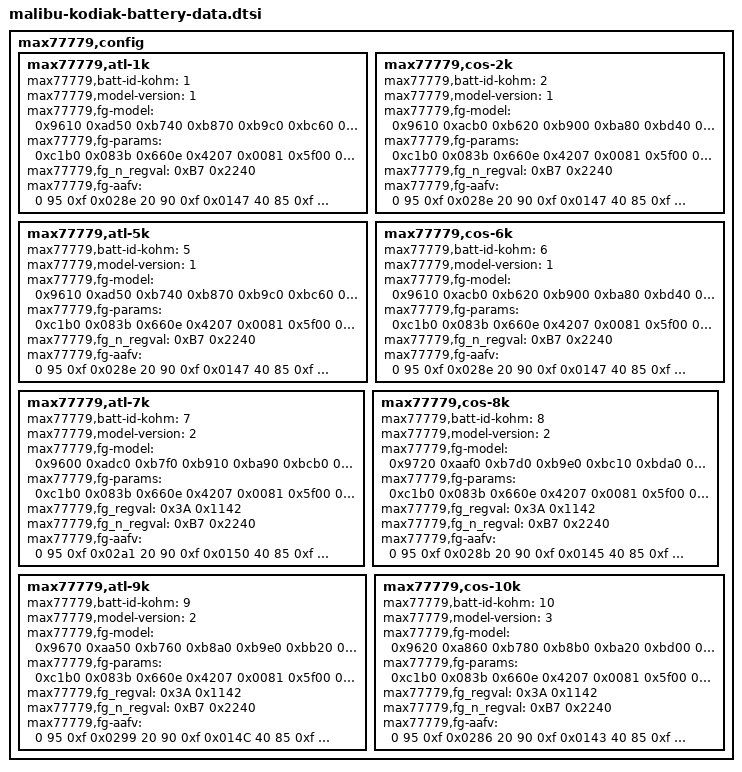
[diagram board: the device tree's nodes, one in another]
// SPDX-License-Identifier: GPL-2.0-only
/*
 * Battery device tree entries
 *
 * Copyright 2025 Google LLC
 *
 */
max77779,config {
	/* PKK4_ATL_3752_001_Proxy_Stacked_G1.ini.txt, b/418260018#comment2 */
	max77779,atl-1k {
		max77779,batt-id-kohm = <1>;
		max77779,model-version = <1>;
		max77779,fg-model = /bits/ 16 <
			0x9610 0xad50 0xb740 0xb870 0xb9c0 0xbc60 0xbe00 0xc100
			0xc2b0 0xc690 0xcaa0 0xcef0 0xd2a0 0xd840 0xdb20 0xdea0
			0x0040 0x01c0 0x1180 0x0c50 0x0d00 0x1260 0x1190 0x0ef0
			0x06d0 0x0700 0x0710 0x06d0 0x06c0 0x07e0 0x06e0 0x06e0
		>;
		max77779,fg-params = /bits/ 16 <
			/* 0x00C0 */	0xc1b0	/* nnvcfg0 */
			/* 0x00B6 */	0x083b	/* nrelaxcfg */
			/* 0x009F */	0x660e	/* nLearnCFG */
			/* 0x000C */	0x4207	/* Config */
			/* 0x00AB */	0x0081	/* Config2 */
			/* 0x00BC */	0x5f00	/* nFullSOCThr */
			/* 0x00A9 */	0x07fc	/* nfullcaprep */
			/* 0x00B3 */	0x07fc	/* ndesigncap */
			/* 0x0046 */	0x0c80	/* dPacc */
			/* 0x00A5 */	0x07fc	/* nfullcapnom */
			/* 0x00C6 */	0xa55a	/* nVEmpty */
			/* 0x00A0 */	0x2e0a	/* nQRTable00 */
			/* 0x00A1 */	0x1582	/* nQRTable10 */
			/* 0x00A2 */	0x0a00	/* nQRTable20 */
			/* 0x00A3 */	0x0780	/* nQRTable30 */
			/* 0x00A6 */	0x0400	/* nRCOMP0 */
			/* 0x00A7 */	0x1402	/* nTempCo */
			/* 0x009C */	0x028e	/* nichgterm */
			/* 0x00B2 */	0x3870	/* nmisccfg */
			/* 0x009E */	0x0400	/* nModelCfg */
			/* 0x00CA */	0xc8ff	/* nThermCfg */
			/* 0x009D */	0xcea4	/* nFilterCfg */
		>;
		max77779,fg_n_regval = /bits/ 16 <
			0xB7 0x2240	/* nConvgCfg */
		>;
		max77779,fg-aafv = /bits/ 32 <
			  0   95  0xf  0x028e
			 20   90  0xf  0x0147
			 40   85  0xf  0x0147
			 60   80  0xf  0x0147
			 80   75  0xf  0x0147
			100   70  0xf  0x0147
		>;
	};

	/* PKK4_COS_3753_001_Proxy_G1.ini.txt, b/418261687#comment3 */
	max77779,cos-2k {
		max77779,batt-id-kohm = <2>;
		max77779,model-version = <1>;
		max77779,fg-model = /bits/ 16 <
			0x9610 0xacb0 0xb620 0xb900 0xba80 0xbd40 0xc030 0xc300
			0xc680 0xca50 0xce10 0xcf00 0xd200 0xd5c0 0xd8c0 0xdfb0
			0x0040 0x0210 0x08b0 0x0c20 0x0ef0 0x0eb0 0x0ff0 0x07e0
			0x06b0 0x06f0 0x0890 0x06b0 0x05f0 0x07e0 0x06f0 0x06f0
		>;
		max77779,fg-params = /bits/ 16 <
			/* 0x00C0 */	0xc1b0	/* nnvcfg0 */
			/* 0x00B6 */	0x083b	/* nrelaxcfg */
			/* 0x009F */	0x660e	/* nLearnCFG */
			/* 0x000C */	0x4207	/* Config */
			/* 0x00AB */	0x0081	/* Config2 */
			/* 0x00BC */	0x5f00	/* nFullSOCThr */
			/* 0x00A9 */	0x07fc	/* nfullcaprep */
			/* 0x00B3 */	0x07fc	/* ndesigncap */
			/* 0x0046 */	0x0c80	/* dPacc */
			/* 0x00A5 */	0x07fc	/* nfullcapnom */
			/* 0x00C6 */	0xa55a	/* nVEmpty */
			/* 0x00A0 */	0x1e0c	/* nQRTable00 */
			/* 0x00A1 */	0x0f06	/* nQRTable10 */
			/* 0x00A2 */	0x0784	/* nQRTable20 */
			/* 0x00A3 */	0x0504	/* nQRTable30 */
			/* 0x00A6 */	0x0380	/* nRCOMP0 */
			/* 0x00A7 */	0x1402	/* nTempCo */
			/* 0x009C */	0x028e	/* nichgterm */
			/* 0x00B2 */	0x3870	/* nmisccfg */
			/* 0x009E */	0x0400	/* nModelCfg */
			/* 0x00CA */	0xc8ff	/* nThermCfg */
			/* 0x009D */	0xcea4	/* nFilterCfg */
		>;
		max77779,fg_n_regval = /bits/ 16 <
			0xB7 0x2240	/* nConvgCfg */
		>;
		max77779,fg-aafv = /bits/ 32 <
			  0   95  0xf  0x028e
			 20   90  0xf  0x0147
			 40   85  0xf  0x0147
			 60   80  0xf  0x0147
			 80   75  0xf  0x0147
			100   70  0xf  0x0147
		>;
	};

	/* PKK4_ATL_3752_001_Proxy_Stacked_G1.ini.txt, b/418260018#comment2 */
	max77779,atl-5k {
		max77779,batt-id-kohm = <5>; /* ATL-W */
		max77779,model-version = <1>;
		max77779,fg-model = /bits/ 16 <
			0x9610 0xad50 0xb740 0xb870 0xb9c0 0xbc60 0xbe00 0xc100
			0xc2b0 0xc690 0xcaa0 0xcef0 0xd2a0 0xd840 0xdb20 0xdea0
			0x0040 0x01c0 0x1180 0x0c50 0x0d00 0x1260 0x1190 0x0ef0
			0x06d0 0x0700 0x0710 0x06d0 0x06c0 0x07e0 0x06e0 0x06e0
		>;
		max77779,fg-params = /bits/ 16 <
			/* 0x00C0 */	0xc1b0	/* nnvcfg0 */
			/* 0x00B6 */	0x083b	/* nrelaxcfg */
			/* 0x009F */	0x660e	/* nLearnCFG */
			/* 0x000C */	0x4207	/* Config */
			/* 0x00AB */	0x0081	/* Config2 */
			/* 0x00BC */	0x5f00	/* nFullSOCThr */
			/* 0x00A9 */	0x07fc	/* nfullcaprep */
			/* 0x00B3 */	0x07fc	/* ndesigncap */
			/* 0x0046 */	0x0c80	/* dPacc */
			/* 0x00A5 */	0x07fc	/* nfullcapnom */
			/* 0x00C6 */	0xa55a	/* nVEmpty */
			/* 0x00A0 */	0x2e0a	/* nQRTable00 */
			/* 0x00A1 */	0x1582	/* nQRTable10 */
			/* 0x00A2 */	0x0a00	/* nQRTable20 */
			/* 0x00A3 */	0x0780	/* nQRTable30 */
			/* 0x00A6 */	0x0400	/* nRCOMP0 */
			/* 0x00A7 */	0x1402	/* nTempCo */
			/* 0x009C */	0x028e	/* nichgterm */
			/* 0x00B2 */	0x3870	/* nmisccfg */
			/* 0x009E */	0x0400	/* nModelCfg */
			/* 0x00CA */	0xc8ff	/* nThermCfg */
			/* 0x009D */	0xcea4	/* nFilterCfg */
		>;
		max77779,fg_n_regval = /bits/ 16 <
			0xB7 0x2240	/* nConvgCfg */
		>;
		max77779,fg-aafv = /bits/ 32 <
			  0   95  0xf  0x028e
			 20   90  0xf  0x0147
			 40   85  0xf  0x0147
			 60   80  0xf  0x0147
			 80   75  0xf  0x0147
			100   70  0xf  0x0147
		>;
	};

	/* PKK4_COS_3753_001_Proxy_G1.ini.txt, b/418261687#comment3 */
	max77779,cos-6k {
		max77779,batt-id-kohm = <6>; /* COS-W */
		max77779,model-version = <1>;
		max77779,fg-model = /bits/ 16 <
			0x9610 0xacb0 0xb620 0xb900 0xba80 0xbd40 0xc030 0xc300
			0xc680 0xca50 0xce10 0xcf00 0xd200 0xd5c0 0xd8c0 0xdfb0
			0x0040 0x0210 0x08b0 0x0c20 0x0ef0 0x0eb0 0x0ff0 0x07e0
			0x06b0 0x06f0 0x0890 0x06b0 0x05f0 0x07e0 0x06f0 0x06f0
		>;
		max77779,fg-params = /bits/ 16 <
			/* 0x00C0 */	0xc1b0	/* nnvcfg0 */
			/* 0x00B6 */	0x083b	/* nrelaxcfg */
			/* 0x009F */	0x660e	/* nLearnCFG */
			/* 0x000C */	0x4207	/* Config */
			/* 0x00AB */	0x0081	/* Config2 */
			/* 0x00BC */	0x5f00	/* nFullSOCThr */
			/* 0x00A9 */	0x07fc	/* nfullcaprep */
			/* 0x00B3 */	0x07fc	/* ndesigncap */
			/* 0x0046 */	0x0c80	/* dPacc */
			/* 0x00A5 */	0x07fc	/* nfullcapnom */
			/* 0x00C6 */	0xa55a	/* nVEmpty */
			/* 0x00A0 */	0x1e0c	/* nQRTable00 */
			/* 0x00A1 */	0x0f06	/* nQRTable10 */
			/* 0x00A2 */	0x0784	/* nQRTable20 */
			/* 0x00A3 */	0x0504	/* nQRTable30 */
			/* 0x00A6 */	0x0380	/* nRCOMP0 */
			/* 0x00A7 */	0x1402	/* nTempCo */
			/* 0x009C */	0x028e	/* nichgterm */
			/* 0x00B2 */	0x3870	/* nmisccfg */
			/* 0x009E */	0x0400	/* nModelCfg */
			/* 0x00CA */	0xc8ff	/* nThermCfg */
			/* 0x009D */	0xcea4	/* nFilterCfg */
		>;
		max77779,fg_n_regval = /bits/ 16 <
			0xB7 0x2240	/* nConvgCfg */
		>;
		max77779,fg-aafv = /bits/ 32 <
			  0   95  0xf  0x028e
			 20   90  0xf  0x0147
			 40   85  0xf  0x0147
			 60   80  0xf  0x0147
			 80   75  0xf  0x0147
			100   70  0xf  0x0147
		>;
	};

	/* PKK4_ATL_4059_StackingD.ini.txt, b/467524492#comment2 */
	max77779,atl-7k {
		max77779,batt-id-kohm = <7>; /* ATL-S-SY-6/9 */
		max77779,model-version = <2>;
		max77779,fg-model = /bits/ 16 <
			0x9600 0xadc0 0xb7f0 0xb910 0xba90 0xbcb0 0xbe40 0xc100
			0xc2e0 0xc620 0xc9c0 0xcd50 0xd090 0xd580 0xdb20 0xe070
			0x0020 0x0180 0x1550 0x0ed0 0x0e40 0x1730 0x10d0 0x0bf0
			0x07e0 0x0730 0x06b0 0x06d0 0x05d0 0x07a0 0x05a0 0x05a0
		>;
		max77779,fg-params = /bits/ 16 <
			/* 0x00C0 */	0xc1b0	/* nnvcfg0 */
			/* 0x00B6 */	0x083b	/* nrelaxcfg */
			/* 0x009F */	0x660e	/* nLearnCFG */
			/* 0x000C */	0x4207	/* Config */
			/* 0x00AB */	0x0081	/* Config2 */
			/* 0x00BC */	0x5f00	/* nFullSOCThr */
			/* 0x00A9 */	0x083a	/* nfullcaprep */
			/* 0x00B3 */	0x083a	/* ndesigncap */
			/* 0x0046 */	0x0c80	/* dPacc */
			/* 0x00A5 */	0x083a	/* nfullcapnom */
			/* 0x00C6 */	0xa55a	/* nVEmpty */
			/* 0x00A0 */	0x280c	/* nQRTable00 */
			/* 0x00A1 */	0x1408	/* nQRTable10 */
			/* 0x00A2 */	0x0a00	/* nQRTable20 */
			/* 0x00A3 */	0x0680	/* nQRTable30 */
			/* 0x00A6 */	0x0440	/* nRCOMP0 */
			/* 0x00A7 */	0x1803	/* nTempCo */
			/* 0x009C */	0x02a1	/* nichgterm */
			/* 0x00B2 */	0x3870	/* nmisccfg */
			/* 0x009E */	0x0400	/* nModelCfg */
			/* 0x00CA */	0xc8ff	/* nThermCfg */
			/* 0x009D */	0xcea4	/* nFilterCfg */
		>;
		max77779,fg_regval = /bits/ 16 <
			0x3A 0x1142	/* SOCHold */
		>;
		max77779,fg_n_regval = /bits/ 16 <
			0xB7 0x2240	/* nConvgCfg */
		>;
		max77779,fg-aafv = /bits/ 32 <
			  0   95  0xf  0x02a1
			 20   90  0xf  0x0150
			 40   85  0xf  0x0150
			 60   80  0xf  0x0150
			 80   75  0xf  0x0150
			100   70  0xf  0x0150
		>;
	};

	/* PKK4_COS_4050_StackingB.ini.txt, b/471328077#comment2 */
	max77779,cos-8k {
		max77779,batt-id-kohm = <8>; /* COS-S_SY-8/10 */
		max77779,model-version = <2>;
		max77779,fg-model = /bits/ 16 <
			0x9720 0xaaf0 0xb7d0 0xb9e0 0xbc10 0xbda0 0xbfe0 0xc270
			0xc650 0xca70 0xce40 0xd1e0 0xd5a0 0xd8f0 0xdce0 0xe040
			0x0040 0x0180 0x1000 0x0ef0 0x1120 0x1250 0x0df0 0x07f0
			0x06c0 0x06b0 0x0660 0x06c0 0x05f0 0x0860 0x05f0 0x05f0
		>;
		max77779,fg-params = /bits/ 16 <
			/* 0x00C0 */	0xc1b0	/* nnvcfg0 */
			/* 0x00B6 */	0x083b	/* nrelaxcfg */
			/* 0x009F */	0x660e	/* nLearnCFG */
			/* 0x000C */	0x4207	/* Config */
			/* 0x00AB */	0x0081	/* Config2 */
			/* 0x00BC */	0x5f00	/* nFullSOCThr */
			/* 0x00A9 */	0x07f4	/* nfullcaprep */
			/* 0x00B3 */	0x07f4	/* ndesigncap */
			/* 0x0046 */	0x0c80	/* dPacc */
			/* 0x00A5 */	0x07f4	/* nfullcapnom */
			/* 0x00C6 */	0xa55a	/* nVEmpty */
			/* 0x00A0 */	0x2810	/* nQRTable00 */
			/* 0x00A1 */	0x1588	/* nQRTable10 */
			/* 0x00A2 */	0x0c82	/* nQRTable20 */
			/* 0x00A3 */	0x0782	/* nQRTable30 */
			/* 0x00A6 */	0x0450	/* nRCOMP0 */
			/* 0x00A7 */	0x1802	/* nTempCo */
			/* 0x009C */	0x028b	/* nichgterm */
			/* 0x00B2 */	0x3870	/* nmisccfg */
			/* 0x009E */	0x0400	/* nModelCfg */
			/* 0x00CA */	0xc8ff	/* nThermCfg */
			/* 0x009D */	0xcea4	/* nFilterCfg */
		>;
		max77779,fg_regval = /bits/ 16 <
			0x3A 0x1142	/* SOCHold */
		>;
		max77779,fg_n_regval = /bits/ 16 <
			0xB7 0x2240	/* nConvgCfg */
		>;
		max77779,fg-aafv = /bits/ 32 <
			  0   95  0xf  0x028b
			 20   90  0xf  0x0145
			 40   85  0xf  0x0145
			 60   80  0xf  0x0145
			 80   75  0xf  0x0145
			100   70  0xf  0x0145
		>;
	};

	/* PKK4_ATL_4058_Stacking B.ini.txt, b/467528159#comment2 */
	max77779,atl-9k {
		max77779,batt-id-kohm = <9>; /* ATL-S-SY-8/10 */
		max77779,model-version = <2>;
		max77779,fg-model = /bits/ 16 <
			0x9670 0xaa50 0xb760 0xb8a0 0xb9e0 0xbb20 0xbc60 0xbde0
			0xbf10 0xc160 0xc4e0 0xc910 0xcda0 0xd2b0 0xd890 0xe010
			0x0040 0x00e0 0x1100 0x0fc0 0x0f00 0x10a0 0x12c0 0x1440
			0x0f90 0x09a0 0x06e0 0x06c0 0x0680 0x06e0 0x0650 0x0650
		>;
		max77779,fg-params = /bits/ 16 <
			/* 0x00C0 */	0xc1b0	/* nnvcfg0 */
			/* 0x00B6 */	0x083b	/* nrelaxcfg */
			/* 0x009F */	0x660e	/* nLearnCFG */
			/* 0x000C */	0x4207	/* Config */
			/* 0x00AB */	0x0081	/* Config2 */
			/* 0x00BC */	0x5f00	/* nFullSOCThr */
			/* 0x00A9 */	0x081f	/* nfullcaprep */
			/* 0x00B3 */	0x081f	/* ndesigncap */
			/* 0x0046 */	0x0c80	/* dPacc */
			/* 0x00A5 */	0x081f	/* nfullcapnom */
			/* 0x00C6 */	0xa55a	/* nVEmpty */
			/* 0x00A0 */	0x2f0d	/* nQRTable00 */
			/* 0x00A1 */	0x1884	/* nQRTable10 */
			/* 0x00A2 */	0x0d00	/* nQRTable20 */
			/* 0x00A3 */	0x0900	/* nQRTable30 */
			/* 0x00A6 */	0x0400	/* nRCOMP0 */
			/* 0x00A7 */	0x1402	/* nTempCo */
			/* 0x009C */	0x0299	/* nichgterm */
			/* 0x00B2 */	0x3870	/* nmisccfg */
			/* 0x009E */	0x0400	/* nModelCfg */
			/* 0x00CA */	0xc8ff	/* nThermCfg */
			/* 0x009D */	0xcea4	/* nFilterCfg */
		>;
		max77779,fg_regval = /bits/ 16 <
			0x3A 0x1142	/* SOCHold */
		>;
		max77779,fg_n_regval = /bits/ 16 <
			0xB7 0x2240	/* nConvgCfg */
		>;
		max77779,fg-aafv = /bits/ 32 <
			  0   95  0xf  0x0299
			 20   90  0xf  0x014C
			 40   85  0xf  0x014C
			 60   80  0xf  0x014C
			 80   75  0xf  0x014C
			100   70  0xf  0x014C
		>;
	};

	/* PKK4_COS_4106_PMMAPOR.ini.txt, b/486979854#comment2 */
	max77779,cos-10k {
		max77779,batt-id-kohm = <10>; /* COS-S-SY-6/9 */
		max77779,model-version = <3>;
		max77779,fg-model = /bits/ 16 <
			0x9620 0xa860 0xb780 0xb8b0 0xba20 0xbd00 0xbe50 0xbfd0
			0xc300 0xc600 0xc970 0xcda0 0xd150 0xd500 0xdc20 0xe080
			0x0030 0x00c0 0x13f0 0x0df0 0x0f00 0x14b0 0x1260 0x0cd0
			0x0790 0x07f0 0x05f0 0x06a0 0x06a0 0x07c0 0x0490 0x0490
		>;
		max77779,fg-params = /bits/ 16 <
			/* 0x00C0 */	0xc1b0	/* nnvcfg0 */
			/* 0x00B6 */	0x083b	/* nrelaxcfg */
			/* 0x009F */	0x660e	/* nLearnCFG */
			/* 0x000C */	0x4207	/* Config */
			/* 0x00AB */	0x0081	/* Config2 */
			/* 0x00BC */	0x5f00	/* nFullSOCThr */
			/* 0x00A9 */	0x0829	/* nfullcaprep */
			/* 0x00B3 */	0x0829	/* ndesigncap */
			/* 0x0046 */	0x0c80	/* dPacc */
			/* 0x00A5 */	0x0829	/* nfullcapnom */
			/* 0x00C6 */	0xa55a	/* nVEmpty */
			/* 0x00A0 */	0x1e12	/* nQRTable00 */
			/* 0x00A1 */	0x1109	/* nQRTable10 */
			/* 0x00A2 */	0x0b00	/* nQRTable20 */
			/* 0x00A3 */	0x0781	/* nQRTable30 */
			/* 0x00A6 */	0x03f0	/* nRCOMP0 */
			/* 0x00A7 */	0x1403	/* nTempCo */
			/* 0x009C */	0x0286	/* nichgterm */
			/* 0x00B2 */	0x3870	/* nmisccfg */
			/* 0x009E */	0x0400	/* nModelCfg */
			/* 0x00CA */	0xc8ff	/* nThermCfg */
			/* 0x009D */	0xcea4	/* nFilterCfg */
		>;
		max77779,fg_regval = /bits/ 16 <
			0x3A 0x1142	/* SOCHold */
		>;
		max77779,fg_n_regval = /bits/ 16 <
			0xB7 0x2240	/* nConvgCfg */
		>;
		max77779,fg-aafv = /bits/ 32 <
			  0   95  0xf  0x0286
			 20   90  0xf  0x0143
			 40   85  0xf  0x0143
			 60   80  0xf  0x0143
			 80   75  0xf  0x0143
			100   70  0xf  0x0143
		>;
	};
};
